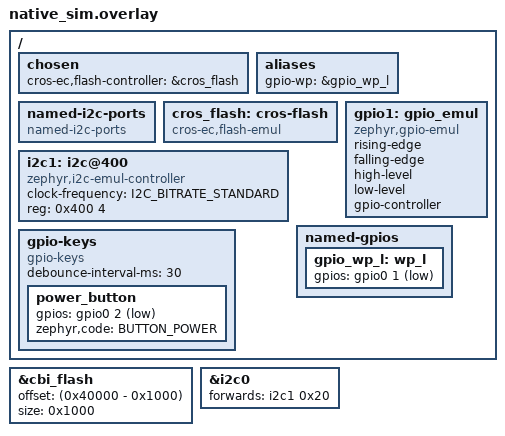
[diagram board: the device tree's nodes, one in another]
/* Copyright 2024 The ChromiumOS Authors
 * Use of this source code is governed by a BSD-style license that can be
 * found in the LICENSE file.
 */

#include <board-overlays/native_sim.dts>
#include <cros/binman.dtsi>
#include <cros/cbi_flash.dtsi>
#include <dt-bindings/buttons.h>
#include <zephyr/dt-bindings/input/input-event-codes.h>

 / {
    chosen {
	    cros-ec,flash-controller = &cros_flash;
    };

    aliases {
        gpio-wp = &gpio_wp_l;
    };

    named-i2c-ports {
	    compatible = "named-i2c-ports";
    };

    cros_flash: cros-flash {
		compatible = "cros-ec,flash-emul";
	};

    gpio1: gpio_emul {
		status = "okay";
		compatible = "zephyr,gpio-emul";
		rising-edge;
		falling-edge;
		high-level;
		low-level;
		gpio-controller;
		#gpio-cells = <2>;
	};


    i2c1: i2c1: i2c@400 {
		status = "okay";
		compatible = "zephyr,i2c-emul-controller";
		clock-frequency = <I2C_BITRATE_STANDARD>;
		#address-cells = <1>;
		#size-cells = <0>;
		#forward-cells = <1>;
		reg = <0x400 4>;
    };


    named-gpios {
        gpio_wp_l: wp_l {
            gpios = <&gpio0 1 (GPIO_INPUT | GPIO_OUTPUT | GPIO_ACTIVE_LOW)>;
        };
    };

    gpio-keys {
        compatible = "gpio-keys";
        debounce-interval-ms = <30>;
		power_button: power_button {
			gpios = <&gpio0 2 (GPIO_ACTIVE_LOW | GPIO_PULL_UP)>;
			/* TODO: use an INPUT_KEY code here. */
			zephyr,code = <BUTTON_POWER>;
		};
    };
};

&cbi_flash {
	offset = <(0x40000 - 0x1000)>;
	size = <0x1000>;
};

&i2c0 {
    forwards = <&i2c1 0x20>;
};
